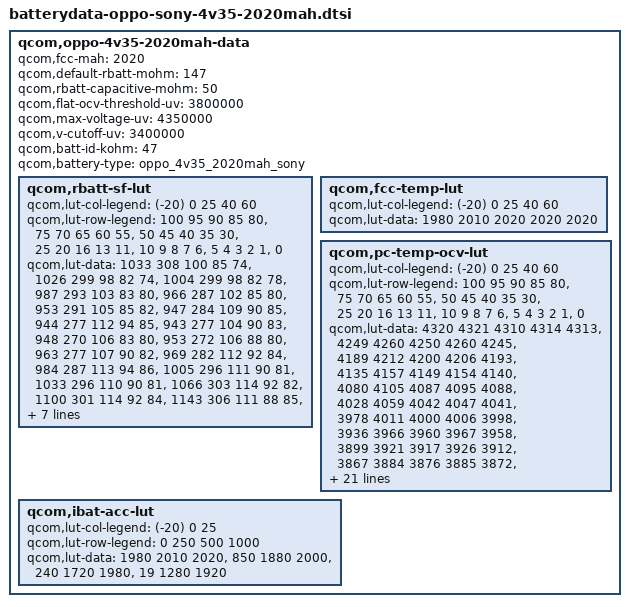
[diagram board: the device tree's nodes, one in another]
/* Copyright (c) 2013, The Linux Foundation. All rights reserved.
 *
 * This program is free software; you can redistribute it and/or modify
 * it under the terms of the GNU General Public License version 2 and
 * only version 2 as published by the Free Software Foundation.
 *
 * This program is distributed in the hope that it will be useful,
 * but WITHOUT ANY WARRANTY; without even the implied warranty of
 * MERCHANTABILITY or FITNESS FOR A PARTICULAR PURPOSE.  See the
 * GNU General Public License for more details.
 */

qcom,oppo-4v35-2020mah-data {
	qcom,fcc-mah = <2020>;
	qcom,default-rbatt-mohm = <147>;
	qcom,rbatt-capacitive-mohm = <50>;
	qcom,flat-ocv-threshold-uv = <3800000>;
	qcom,max-voltage-uv = <4350000>;
	qcom,v-cutoff-uv = <3400000>;
	//qcom,chg-term-ua = <100000>;
	qcom,batt-id-kohm = <47>;
	qcom,battery-type = "oppo_4v35_2020mah_sony";

	qcom,rbatt-sf-lut {
		qcom,lut-col-legend = <(-20) 0 25 40 60>;
		qcom,lut-row-legend = <100 95 90 85 80>,
				<75 70 65 60 55>,
				<50 45 40 35 30>,
				<25 20 16 13 11>,
				<10 9 8 7 6>,
				<5 4 3 2 1>,
				<0>;
		qcom,lut-data = <1033 308 100 85 74>,
   				<1026 299 98 82 74>,
   				<1004 299 98 82 78>,
   				<987 293 103 83 80>,
   				<966 287 102 85 80>,
   				<953 291 105 85 82>,
   				<947 284 109 90 85>,
   				<944 277 112 94 85>,
  				<943 277 104 90 83>,
   				<948 270 106 83 80>,
   				<953 272 106 88 80>,
   				<963 277 107 90 82>,
   				<969 282 112 92 84>,
   				<984 287 113 94 86>,
   				<1005 296 111 90 81>,
   				<1033 296 110 90 81>,
   				<1066 303 114 92 82>,
   				<1100 301 114 92 84>,
   				<1143 306 111 88 85>,
   				<1183 313 114 92 85>,
   				<1213 320 116 94 86>,
   				<1247 328 120 94 90>,
   				<1285 335 121 95 88>,
   				<1338 344 123 100 87>,
   				<1404 359 116 97 89>,
   				<1483 359 120 94 89>,
  				<1594 374 124 99 92>,
   				<1744 412 128 109 100>,
   				<2000 474 135 112 115>,
   				<5000 605 150 133 227>,
   				<135251 124940 300 293 300>;
		};

	qcom,fcc-temp-lut {
		qcom,lut-col-legend = <(-20) 0 25 40 60>;
		qcom,lut-data = <1980 2010 2020 2020 2020>;
	};
				
	qcom,pc-temp-ocv-lut {
		qcom,lut-col-legend = <(-20) 0 25 40 60>;
		qcom,lut-row-legend = <100 95 90 85 80>,
				<75 70 65 60 55>,
				<50 45 40 35 30>,
				<25 20 16 13 11>,
				<10 9 8 7 6>,
				<5 4 3 2 1>,
				<0>;
		//qcom,lut-data = <4332 4333 4322	4327 4313>,
		//		<4249 4267 4257 4262 4248>,
		qcom,lut-data = <4320 4321 4310	4314 4313>,
				<4249 4260 4250 4260 4245>,
				<4189 4212 4200	4206 4193>,
				<4135 4157 4149	4154 4140>,
				<4080 4105 4087	4095 4088>,
				<4028 4059 4042	4047 4041>,
				<3978 4011 4000	4006 3998>,
				<3936 3966 3960	3967 3958>,
				<3899 3921 3917	3926 3912>,
				<3867 3884 3876	3885 3872>,
				<3844 3847 3842	3850 3843>,
				<3818 3825 3819	3828 3821>,
				<3795 3807 3802	3811 3799>,
				<3780 3792 3788	3797 3781>,
				<3765 3781 3773	3779 3748>,
				<3750 3767 3752	3754 3723>,
				<3732 3749 3735	3735 3703>,
				<3711 3726 3710	3712 3682>,
				<3694 3707 3689	3690 3666>,
				<3681 3693 3681	3684 3661>,
				<3675 3690 3679	3682 3657>,
				<3669 3684 3676	3677 3652>,
				<3661 3678 3671	3673 3637>,
				<3652 3671 3662	3662 3607>,
				<3642 3657 3637	3635 3568>,
				<3628 3622 3600	3594 3520>,
				<3609 3573 3551	3545 3460>,
				<3588 3510 3489	3486 3382>,
				<3494 3428 3406	3402 3272>,
				<3213 3299 3284	3283 3100>,
				<3000 3000 3000	3000 3000>;

		};

	qcom,ibat-acc-lut {
		qcom,lut-col-legend = <(-20) 0 25>;
		qcom,lut-row-legend = <0 250 500 1000>;
		qcom,lut-data = <1980 2010 2020>,
				<850 1880 2000>,
				<240 1720 1980>,
				<19 1280 1920>;
	};

};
